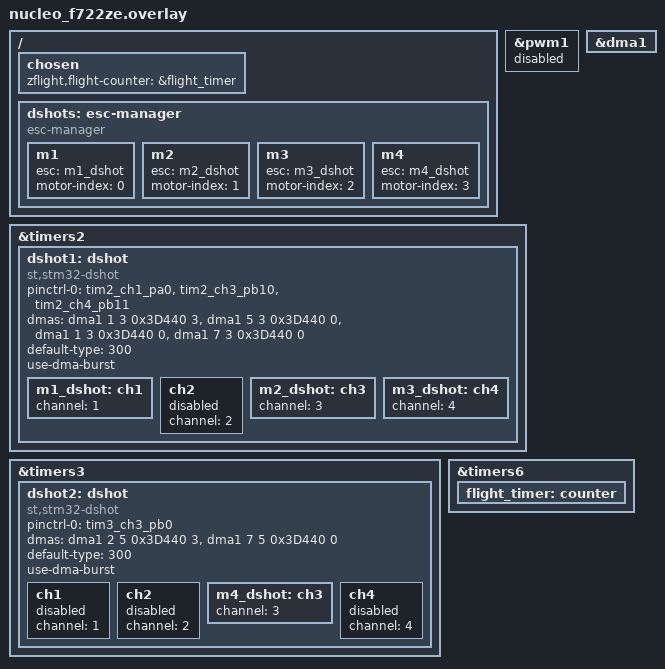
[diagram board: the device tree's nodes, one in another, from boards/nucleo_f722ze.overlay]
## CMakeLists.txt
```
# zflight application
#
# Copyright (c) 2024 Arthur Eichelberger
# SPDX-License-Identifier: Apache-2.0

cmake_minimum_required(VERSION 3.13.1)

# Check the required build args were supplied
if (NOT DEFINED NUM_MOTORS)
    message(FATAL_ERROR "NUM_MOTORS not set")
else()
    set(ENV{NUM_MOTORS} ${NUM_MOTORS})
endif()
if (NOT DEFINED ESC_TYPE)
    message(FATAL_ERROR "ESC_TYPE not set")
endif()

# Set important directories
set(WORKSPACE_DIR ${CMAKE_CURRENT_LIST_DIR}/../..)
set(ENV{ZEPHYR_BASE} ${WORKSPACE_DIR}/zephyr)
set(ZEPHYR_SDK_INSTALL_DIR ${WORKSPACE_DIR}/zephyr-sdk)
set(APP_DIR ${WORKSPACE_DIR}/app)
set(ZFLIGHT_DIR ${APP_DIR}/zflight)

# Set snippets from inputs
set(ESC_TYPE_SNIPPET esc-${ESC_TYPE})
list(APPEND SNIPPET ${ESC_TYPE_SNIPPET})

# Configure Zephyr
find_package(Zephyr REQUIRED HINTS $ENV{ZEPHYR_BASE})
project(zflight LANGUAGES C)

# Configure zflight source
target_include_directories(app PRIVATE include)
file(GLOB_RECURSE SRCS src/*.c)
target_sources(app PRIVATE ${SRCS})
```

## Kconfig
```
# Copyright (c) 2024 Arthur Eichelberger
# SPDX-License-Identifier: Apache-2.0

menu "zflight"
source "Kconfig.zephyr"
endmenu

module = ZFLIGHT
module-str = ZFLIGHT
source "subsys/logging/Kconfig.template.log_config"

config ZFLIGHT_NUM_MOTORS
	int
    default $(NUM_MOTORS)
	help
	  Configure the number of motors on the platform.

config ZFLIGHT_DSHOT
    bool
    default y
    depends on DSHOT

config ZFLIGHT_DSHOT_BIDIR
    bool "Configure zflight to use Bidirectional DShot"
    default y
    depends on DSHOT && FC_HAS_DSHOT_BIDIR
    imply DSHOT_BIDIR
```

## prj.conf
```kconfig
# This file is used to configure the required systems for all platforms.

# Config the bin file name
CONFIG_KERNEL_BIN_NAME="zflight"

# Enable Counters
CONFIG_COUNTER=y

# Enable GPIO
CONFIG_GPIO=y

# Enable UART
CONFIG_SERIAL=y

# Enable terminal
CONFIG_CONSOLE=y
CONFIG_UART_CONSOLE=y
CONFIG_LOG=y
CONFIG_LOG_BACKEND_UART=y # maybe switch to shell backend?
CONFIG_SHELL=y
CONFIG_SHELL_MINIMAL=y
CONFIG_SHELL_AUTOSTART=y

# Enable State Machine Framework
CONFIG_SMF=y

# Test features
CONFIG_NO_OPTIMIZATIONS=y
CONFIG_OUTPUT_DISASSEMBLY=y
CONFIG_SHELL_BACKEND_SERIAL_INTERRUPT_DRIVEN=y
CONFIG_DSHOT_BIDIR=n # untested
CONFIG_DSHOT_STM32_DMA_BURST=n # untested
```

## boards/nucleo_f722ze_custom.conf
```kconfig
# This file is used to configure the required systems for all platforms.

CONFIG_PLATFORM_ESC_DSHOT=y
```

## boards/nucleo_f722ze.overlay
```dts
/*
 * Copyright (c) 2024 Arthur Eichelberger
 *
 * SPDX-License-Identifier: Apache-2.0
 */

/ {
	chosen {
		zflight,flight-counter = &flight_timer;
	};

	dshots: esc-manager {
		compatible = "esc-manager";
		m1 {
			esc = <&m1_dshot>;
			motor-index = <0>;
		};
		m2 {
			esc = <&m2_dshot>;
			motor-index = <1>;
		};
		m3 {
			esc = <&m3_dshot>;
			motor-index = <2>;
		};
		m4 {
			esc = <&m4_dshot>;
			motor-index = <3>;
		};
	};
};

&pwm1 {
    status = "disabled";
};

&dma1 {
    status = "okay";
};

&timers2 {
	status = "okay";
	dshot1: dshot {
		compatible = "st,stm32-dshot";
		pinctrl-0 = <&tim2_ch1_pa0>,
					<&tim2_ch3_pb10>,
					<&tim2_ch4_pb11>;
		pinctrl-names = "default";
		dmas =  <&dma1 1 3 0x3D440 3>,
				<&dma1 5 3 0x3D440 0>,
				<&dma1 1 3 0x3D440 0>,
				<&dma1 7 3 0x3D440 0>;
		dma-names = "up", "ch1", "ch3", "ch4";
		default-type = <300>;
		use-dma-burst;
		#esc-cells = <1>;
		m1_dshot: ch1 {
			channel = <1>;
			status = "okay";
		};
		ch2 {
			channel = <2>;
			status = "disabled";
		};
		m2_dshot: ch3 {
			channel = <3>;
			status = "okay";
		};
		m3_dshot: ch4 {
			channel = <4>;
			status = "okay";
		};
		status = "okay";
	};
};

&timers3 {
	status = "okay";
	dshot2: dshot {
		compatible = "st,stm32-dshot";
		pinctrl-0 = <&tim3_ch3_pb0>;
		pinctrl-names = "default";
		dmas =  <&dma1 2 5 0x3D440 3>,
				<&dma1 7 5 0x3D440 0>;
		dma-names = "up", "ch3";
		default-type = <300>;
		use-dma-burst;
		#esc-cells = <1>;
		ch1 {
			channel = <1>;
			status = "disabled";
		};
		ch2 {
			channel = <2>;
			status = "disabled";
		};
		m4_dshot: ch3 {
			channel = <3>;
			status = "okay";
		};
		ch4 {
			channel = <4>;
			status = "disabled";
		};
		status = "okay";
	};
};

&timers6 {
	status = "okay";
	flight_timer: counter {
		status = "okay";
	};
};
```

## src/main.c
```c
/*
 * Copyright (c) 2016 Intel Corporation
 *
 * SPDX-License-Identifier: Apache-2.0
 */

#include <stdio.h>
#include <zephyr/kernel.h>
#include <zephyr/drivers/gpio.h>

/* 1000 msec = 1 sec */
#define SLEEP_TIME_MS   1000

/* The devicetree node identifier for the "led0" alias. */
#define LED0_NODE DT_ALIAS(led0)

/*
 * A build error on this line means your board is unsupported.
 * See the sample documentation for information on how to fix this.
 */
static const struct gpio_dt_spec led = GPIO_DT_SPEC_GET(LED0_NODE, gpios);

int main(void)
{
	int ret;

	if (!gpio_is_ready_dt(&led)) {
		return 0;
	}

	ret = gpio_pin_configure_dt(&led, GPIO_OUTPUT_ACTIVE);
	if (ret < 0) {
		return 0;
	}

	while (1) {
		ret = gpio_pin_toggle_dt(&led);
		if (ret < 0) {
			return 0;
		}

		k_msleep(SLEEP_TIME_MS);
	}
	return ret;
}
```
